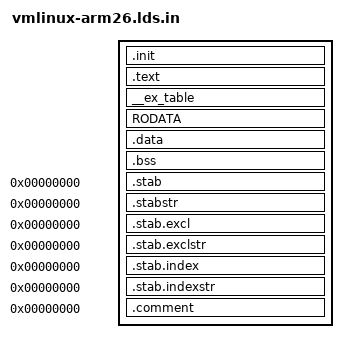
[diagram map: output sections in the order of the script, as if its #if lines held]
/* ld script to make ARM Linux kernel
 * taken from the i386 version by Russell King
 * Written by Martin Mares <mj@atrey.karlin.mff.cuni.cz>
 * borrowed from Russels ARM port by Ian Molton and subsequently modified.
 */

#include <asm-generic/vmlinux.lds.h>

OUTPUT_ARCH(arm)
ENTRY(stext)
jiffies = jiffies_64;
SECTIONS
{
	. = TEXTADDR;
	.init : {			/* Init code and data		*/
		_stext = .;
		__init_begin = .;
			_sinittext = .;
			*(.init.text)
			_einittext = .;
		__proc_info_begin = .;
			*(.proc.info)
		__proc_info_end = .;
		__arch_info_begin = .;
			*(.arch.info)
		__arch_info_end = .;
		__tagtable_begin = .;
			*(.taglist)
		__tagtable_end = .;
			*(.init.data)
		. = ALIGN(16);
		__setup_start = .;
			*(.init.setup)
		__setup_end = .;
		__early_begin = .;
			*(__early_param)
		__early_end = .;
		__initcall_start = .;
			*(.initcall1.init)
			*(.initcall2.init)
			*(.initcall3.init)
			*(.initcall4.init)
			*(.initcall5.init)
			*(.initcall6.init)
			*(.initcall7.init)
		__initcall_end = .;
		__con_initcall_start = .;
			*(.con_initcall.init)
		__con_initcall_end = .;
#ifdef CONFIG_BLK_DEV_INITRD
		. = ALIGN(32);
		__initramfs_start = .;
			usr/built-in.o(.init.ramfs)
		__initramfs_end = .;
#endif
		. = ALIGN(32768);
		__init_end = .;
	}

	/DISCARD/ : {			/* Exit code and data		*/
		*(.exit.text)
		*(.exit.data)
		*(.exitcall.exit)
	}

	.text : {			/* Real text segment		*/
		_text = .;		/* Text and read-only data	*/
			TEXT_TEXT
			SCHED_TEXT
			LOCK_TEXT
			*(.fixup)
			*(.gnu.warning)
			*(.rodata)
			*(.rodata.*)
			*(.glue_7)
			*(.glue_7t)
		*(.got)			/* Global offset table		*/

		_etext = .;		/* End of text section		*/
	}

	. = ALIGN(16);
	__ex_table : {			/* Exception table		*/
		__start___ex_table = .;
			*(__ex_table)
		__stop___ex_table = .;
	}

	RODATA

	. = ALIGN(8192);

	.data : {
		/*
		 * first, the init task union, aligned
		 * to an 8192 byte boundary. (see arm26/kernel/init_task.c)
		 */
		*(.init.task)

		/*
		 * The cacheline aligned data
		 */
		. = ALIGN(32);
		*(.data.cacheline_aligned)

		/*
		 * and the usual data section
		 */
		DATA_DATA
		CONSTRUCTORS

		_edata = .;
	}

	.bss : {
		__bss_start = .;	/* BSS				*/
		*(.bss)
		*(COMMON)
		_end = . ;
	}
					/* Stabs debugging sections.	*/
	.stab 0 : { *(.stab) }
	.stabstr 0 : { *(.stabstr) }
	.stab.excl 0 : { *(.stab.excl) }
	.stab.exclstr 0 : { *(.stab.exclstr) }
	.stab.index 0 : { *(.stab.index) }
	.stab.indexstr 0 : { *(.stab.indexstr) }
	.comment 0 : { *(.comment) }
}
